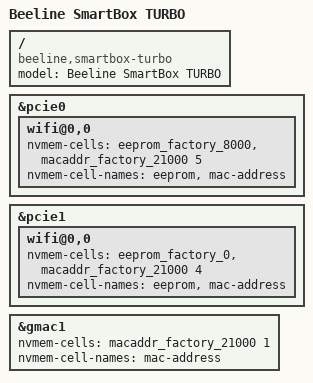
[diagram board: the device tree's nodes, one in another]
// SPDX-License-Identifier: GPL-2.0-or-later OR MIT

#include "mt7621_sercomm_dxx_nand_256m.dtsi"

/ {
	compatible = "beeline,smartbox-turbo", "mediatek,mt7621-soc";
	model = "Beeline SmartBox TURBO";
};

&pcie0 {
	wifi@0,0 {
		nvmem-cells = <&eeprom_factory_8000>, <&macaddr_factory_21000 5>;
		nvmem-cell-names = "eeprom", "mac-address";
	};
};

&pcie1 {
	wifi@0,0 {
		nvmem-cells = <&eeprom_factory_0>, <&macaddr_factory_21000 4>;
		nvmem-cell-names = "eeprom", "mac-address";
	};
};

&gmac1 {
	nvmem-cells = <&macaddr_factory_21000 1>;
	nvmem-cell-names = "mac-address";
};
